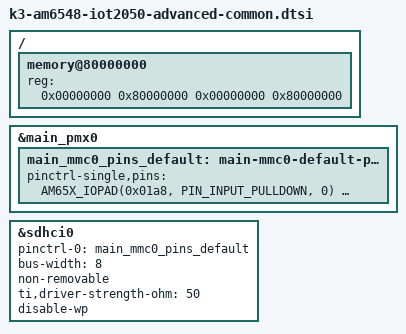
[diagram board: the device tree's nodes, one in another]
/dts-v1/;
#include "k3-am65-iot2050-common.dtsi"
/ {
	memory@80000000 {
		device_type = "memory";
		reg = <0x00000000 0x80000000 0x00000000 0x80000000>;
	};
};
&main_pmx0 {
	main_mmc0_pins_default: main-mmc0-default-pins {
		pinctrl-single,pins = <
			AM65X_IOPAD(0x01a8, PIN_INPUT_PULLDOWN, 0)   
			AM65X_IOPAD(0x01ac, PIN_INPUT_PULLUP,   0)   
			AM65X_IOPAD(0x01a4, PIN_INPUT_PULLUP,   0)   
			AM65X_IOPAD(0x01a0, PIN_INPUT_PULLUP,   0)   
			AM65X_IOPAD(0x019c, PIN_INPUT_PULLUP,   0)   
			AM65X_IOPAD(0x0198, PIN_INPUT_PULLUP,   0)   
			AM65X_IOPAD(0x0194, PIN_INPUT_PULLUP,   0)   
			AM65X_IOPAD(0x0190, PIN_INPUT_PULLUP,   0)   
			AM65X_IOPAD(0x018c, PIN_INPUT_PULLUP,   0)   
			AM65X_IOPAD(0x0188, PIN_INPUT_PULLUP,   0)   
			AM65X_IOPAD(0x01b8, PIN_OUTPUT_PULLUP,  7)   
			AM65X_IOPAD(0x01b4, PIN_INPUT_PULLUP,   0)   
			AM65X_IOPAD(0x01b0, PIN_INPUT,          0)   
		>;
	};
};
&sdhci0 {
	pinctrl-names = "default";
	pinctrl-0 = <&main_mmc0_pins_default>;
	bus-width = <8>;
	non-removable;
	ti,driver-strength-ohm = <50>;
	disable-wp;
};
